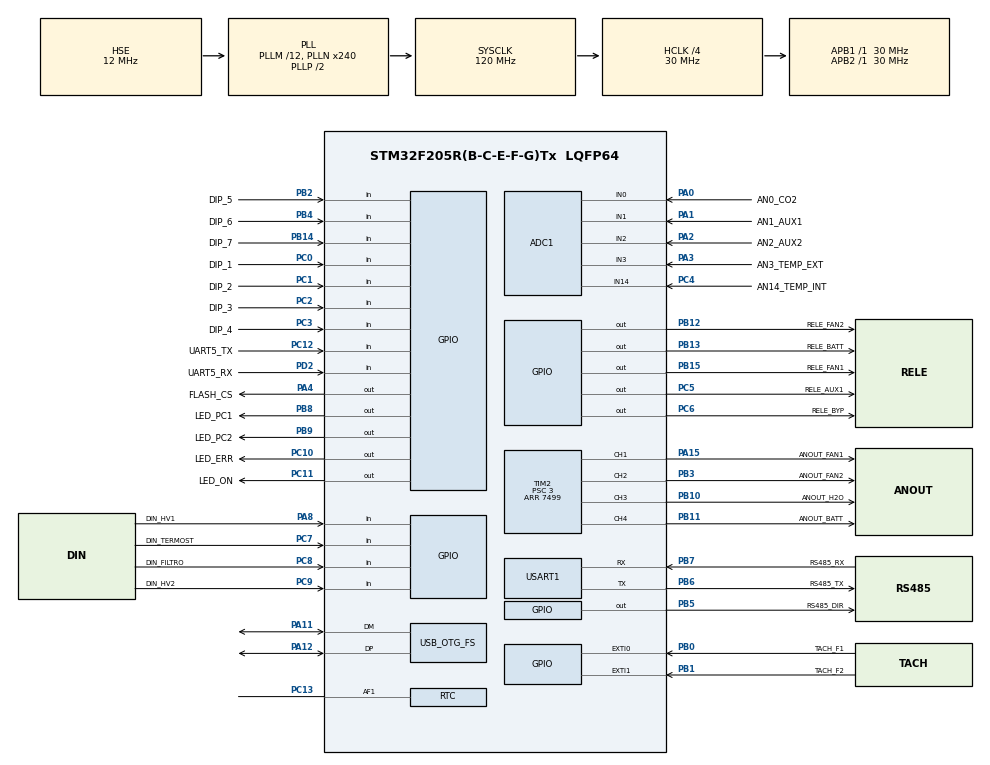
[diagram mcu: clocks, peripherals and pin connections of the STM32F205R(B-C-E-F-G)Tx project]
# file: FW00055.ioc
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ADC1.Channel-0\#ChannelRegularConversion=ADC_CHANNEL_0
ADC1.Channel-1\#ChannelRegularConversion=ADC_CHANNEL_1
ADC1.Channel-2\#ChannelRegularConversion=ADC_CHANNEL_2
ADC1.Channel-3\#ChannelRegularConversion=ADC_CHANNEL_3
ADC1.Channel-4\#ChannelRegularConversion=ADC_CHANNEL_14
ADC1.ClockPrescaler=ADC_CLOCK_SYNC_PCLK_DIV2
ADC1.ContinuousConvMode=DISABLE
ADC1.DMAContinuousRequests=ENABLE
ADC1.EOCSelection=ADC_EOC_SEQ_CONV
ADC1.NbrOfConversion=5
ADC1.NbrOfConversionFlag=1
ADC1.Rank-0\#ChannelRegularConversion=1
ADC1.Rank-1\#ChannelRegularConversion=2
ADC1.Rank-2\#ChannelRegularConversion=3
ADC1.Rank-3\#ChannelRegularConversion=4
ADC1.Rank-4\#ChannelRegularConversion=5
ADC1.SamplingTime-0\#ChannelRegularConversion=ADC_SAMPLETIME_480CYCLES
ADC1.SamplingTime-1\#ChannelRegularConversion=ADC_SAMPLETIME_480CYCLES
ADC1.SamplingTime-2\#ChannelRegularConversion=ADC_SAMPLETIME_480CYCLES
ADC1.SamplingTime-3\#ChannelRegularConversion=ADC_SAMPLETIME_480CYCLES
ADC1.SamplingTime-4\#ChannelRegularConversion=ADC_SAMPLETIME_480CYCLES
ADC1.ScanConvMode=ENABLE
ADC1.master=1
Dma.ADC1.0.Direction=DMA_PERIPH_TO_MEMORY
Dma.ADC1.0.FIFOMode=DMA_FIFOMODE_DISABLE
Dma.ADC1.0.Instance=DMA2_Stream0
Dma.ADC1.0.MemDataAlignment=DMA_MDATAALIGN_HALFWORD
Dma.ADC1.0.MemInc=DMA_MINC_ENABLE
Dma.ADC1.0.Mode=DMA_CIRCULAR
Dma.ADC1.0.PeriphDataAlignment=DMA_PDATAALIGN_HALFWORD
Dma.ADC1.0.PeriphInc=DMA_PINC_DISABLE
Dma.ADC1.0.Priority=DMA_PRIORITY_LOW
Dma.Request0=ADC1
IWDG.Prescaler=IWDG_PRESCALER_16
Mcu.Family=STM32F2
Mcu.Name=STM32F205R(B-C-E-F-G)Tx
Mcu.Package=LQFP64
NVIC.DMA2_Stream0_IRQn=true\:0\:0\:false\:false\:true\:false\:true
NVIC.EXTI0_IRQn=true\:0\:0\:false\:false\:true\:true\:true
NVIC.EXTI1_IRQn=true\:0\:0\:false\:false\:true\:true\:true
NVIC.OTG_FS_IRQn=true\:0\:0\:false\:false\:true\:false\:true
NVIC.PriorityGroup=NVIC_PRIORITYGROUP_4
NVIC.USART1_IRQn=true\:0\:0\:false\:false\:true\:true\:true
PA0-WKUP.GPIO_Label=AN0_CO2
PA0-WKUP.Signal=ADCx_IN0
PA1.GPIO_Label=AN1_AUX1
PA1.Signal=ADCx_IN1
PA10.Signal=USB_OTG_FS_ID
PA11.Mode=Device_Only
PA11.Signal=USB_OTG_FS_DM
PA12.Mode=Device_Only
PA12.Signal=USB_OTG_FS_DP
PA13.Signal=SYS_JTMS-SWDIO
PA14.Signal=SYS_JTCK-SWCLK
PA15.GPIO_Label=ANOUT_FAN1
PA15.Signal=S_TIM2_CH1_ETR
PA2.GPIO_Label=AN2_AUX2
PA2.Signal=ADCx_IN2
PA3.GPIO_Label=AN3_TEMP_EXT
PA3.Signal=ADCx_IN3
PA4.GPIO_Label=FLASH_CS
PA4.Signal=GPIO_Output
PA5.GPIO_Label=FLASH_SCK
PA5.Signal=SPI1_SCK
PA6.GPIO_Label=FLASH_MISO
PA6.Signal=SPI1_MISO
PA7.GPIO_Label=FLASH_MOSI
PA7.Signal=SPI1_MOSI
PA8.GPIO_Label=DIN_HV1
PA8.Signal=GPIO_Input
PA9.Signal=USB_OTG_FS_VBUS
PB0.GPIO_Label=TACH_F1
PB0.Signal=GPXTI0
PB1.GPIO_Label=TACH_F2
PB1.Signal=GPXTI1
PB10.GPIO_Label=ANOUT_H2O
PB10.Signal=S_TIM2_CH3
PB11.GPIO_Label=ANOUT_BATT
PB11.Signal=S_TIM2_CH4
PB12.GPIO_Label=RELE_FAN2
PB12.Signal=GPIO_Output
PB13.GPIO_Label=RELE_BATT
PB13.Signal=GPIO_Output
PB14.GPIO_Label=DIP_7
PB14.GPIO_PuPd=GPIO_PULLUP
PB14.Signal=GPIO_Input
PB15.GPIO_Label=RELE_FAN1
PB15.Signal=GPIO_Output
PB2.GPIO_Label=DIP_5
PB2.GPIO_PuPd=GPIO_PULLUP
PB2.Signal=GPIO_Input
PB3.GPIO_Label=ANOUT_FAN2
PB3.Signal=S_TIM2_CH2
PB4.GPIO_Label=DIP_6
PB4.GPIO_PuPd=GPIO_PULLUP
PB4.Signal=GPIO_Input
PB5.GPIO_Label=RS485_DIR
PB5.Signal=GPIO_Output
PB6.GPIO_Label=RS485_TX
PB6.GPIO_PuPd=GPIO_PULLUP
PB6.Mode=Asynchronous
PB6.Signal=USART1_TX
PB7.GPIO_Label=RS485_RX
PB7.Mode=Asynchronous
PB7.Signal=USART1_RX
PB8.GPIO_Label=LED_PC1
PB8.PinState=GPIO_PIN_SET
PB8.Signal=GPIO_Output
PB9.GPIO_Label=LED_PC2
PB9.PinState=GPIO_PIN_SET
PB9.Signal=GPIO_Output
PC0.GPIO_Label=DIP_1
PC0.GPIO_PuPd=GPIO_PULLUP
PC0.Signal=GPIO_Input
PC1.GPIO_Label=DIP_2
PC1.GPIO_PuPd=GPIO_PULLUP
PC1.Signal=GPIO_Input
PC10.GPIO_Label=LED_ERR
PC10.PinState=GPIO_PIN_SET
PC10.Signal=GPIO_Output
PC11.GPIO_Label=LED_ON
PC11.PinState=GPIO_PIN_SET
PC11.Signal=GPIO_Output
PC12.GPIO_Label=UART5_TX
PC12.GPIO_PuPd=GPIO_PULLUP
PC12.Signal=GPIO_Input
PC13.Mode=Calibration_512Hz
PC13.Signal=RTC_AF1
PC14-OSC32_IN.Mode=LSE-External-Oscillator
PC14-OSC32_IN.Signal=RCC_OSC32_IN
PC15-OSC32_OUT.Mode=LSE-External-Oscillator
PC15-OSC32_OUT.Signal=RCC_OSC32_OUT
PC2.GPIO_Label=DIP_3
PC2.GPIO_PuPd=GPIO_PULLUP
PC2.Signal=GPIO_Input
PC3.GPIO_Label=DIP_4
PC3.GPIO_PuPd=GPIO_PULLUP
PC3.Signal=GPIO_Input
PC4.GPIO_Label=AN14_TEMP_INT
PC4.Signal=ADCx_IN14
PC5.GPIO_Label=RELE_AUX1
PC5.Signal=GPIO_Output
PC6.GPIO_Label=RELE_BYP
PC6.Signal=GPIO_Output
PC7.GPIO_Label=DIN_TERMOST
PC7.Signal=GPIO_Input
PC8.GPIO_Label=DIN_FILTRO
PC8.Signal=GPIO_Input
PC9.GPIO_Label=DIN_HV2
PC9.Signal=GPIO_Input
PD2.GPIO_Label=UART5_RX
PD2.GPIO_PuPd=GPIO_PULLUP
PD2.Signal=GPIO_Input
PH0-OSC_IN.Mode=HSE-External-Oscillator
PH0-OSC_IN.Signal=RCC_OSC_IN
PH1-OSC_OUT.Mode=HSE-External-Oscillator
PH1-OSC_OUT.Signal=RCC_OSC_OUT
ProjectManager.HeapSize=0x800
ProjectManager.StackSize=0x1000
ProjectManager.TargetToolchain=TrueSTUDIO
RCC.48MHZClocksFreq_Value=48000000
RCC.AHBCLKDivider=RCC_SYSCLK_DIV4
RCC.AHBFreq_Value=30000000
RCC.APB1Freq_Value=30000000
RCC.APB1TimFreq_Value=30000000
RCC.APB2Freq_Value=30000000
RCC.APB2TimFreq_Value=30000000
RCC.CortexFreq_Value=30000000
RCC.HCLKFreq_Value=30000000
RCC.HSE_VALUE=12000000
RCC.HSI_VALUE=16000000
RCC.PLLM=12
RCC.PLLN=240
RCC.PLLQ=5
RCC.PLLSourceVirtual=RCC_PLLSOURCE_HSE
RCC.RCC_RTC_Clock_Source=RCC_RTCCLKSOURCE_LSE
RCC.RCC_RTC_Clock_SourceVirtual=RCC_RTCCLKSOURCE_LSE
RCC.SYSCLKFreq_VALUE=120000000
RCC.SYSCLKSource=RCC_SYSCLKSOURCE_PLLCLK
RCC.VCOOutputFreq_Value=240000000
SH.ADCx_IN0.0=ADC1_IN0,IN0
SH.ADCx_IN1.0=ADC1_IN1,IN1
SH.ADCx_IN14.0=ADC1_IN14,IN14
SH.ADCx_IN2.0=ADC1_IN2,IN2
SH.ADCx_IN3.0=ADC1_IN3,IN3
SH.S_TIM2_CH1_ETR.0=TIM2_CH1,PWM Generation1 CH1
SH.S_TIM2_CH2.0=TIM2_CH2,PWM Generation2 CH2
SH.S_TIM2_CH3.0=TIM2_CH3,PWM Generation3 CH3
SH.S_TIM2_CH4.0=TIM2_CH4,PWM Generation4 CH4
TIM2.Channel-PWM\ Generation1\ CH1=TIM_CHANNEL_1
TIM2.Channel-PWM\ Generation2\ CH2=TIM_CHANNEL_2
TIM2.Channel-PWM\ Generation3\ CH3=TIM_CHANNEL_3
TIM2.Channel-PWM\ Generation4\ CH4=TIM_CHANNEL_4
TIM2.Period=7499
TIM2.Prescaler=3
USART1.VirtualMode=VM_ASYNC
USB_DEVICE.CLASS_NAME_FS=CDC
USB_DEVICE.VirtualMode-CDC_FS=Cdc
USB_DEVICE.VirtualModeFS=Cdc_FS
USB_OTG_FS.VirtualMode=Device_Only
VP_CRC_VS_CRC.Mode=CRC_Activate
VP_IWDG_VS_IWDG.Mode=IWDG_Activate
VP_RTC_VS_RTC_Activate.Mode=RTC_Enabled
VP_TIM2_VS_ClockSourceINT.Mode=Internal
VP_USB_DEVICE_VS_USB_DEVICE_CDC_FS.Mode=CDC_FS
board=custom

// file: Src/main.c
/* USER CODE BEGIN Header */
/**
  ******************************************************************************
  * @file           : main.c
  * @brief          : Main program body
  ******************************************************************************
  ** This notice applies to any and all portions of this file
  * that are not between comment pairs USER CODE BEGIN and
  * USER CODE END. Other portions of this file, whether
  * inserted by the user or by software development tools
  * are owned by their respective copyright owners.
  *
  * COPYRIGHT(c) 2019 STMicroelectronics
  *
  * Redistribution and use in source and binary forms, with or without modification,
  * are permitted provided that the following conditions are met:
  *   1. Redistributions of source code must retain the above copyright notice,
  *      this list of conditions and the following disclaimer.
  *   2. Redistributions in binary form must reproduce the above copyright notice,
  *      this list of conditions and the following disclaimer in the documentation
  *      and/or other materials provided with the distribution.
  *   3. Neither the name of STMicroelectronics nor the names of its contributors
  *      may be used to endorse or promote products derived from this software
  *      without specific prior written permission.
  *
  * THIS SOFTWARE IS PROVIDED BY THE COPYRIGHT HOLDERS AND CONTRIBUTORS "AS IS"
  * AND ANY EXPRESS OR IMPLIED WARRANTIES, INCLUDING, BUT NOT LIMITED TO, THE
  * IMPLIED WARRANTIES OF MERCHANTABILITY AND FITNESS FOR A PARTICULAR PURPOSE ARE
  * DISCLAIMED. IN NO EVENT SHALL THE COPYRIGHT HOLDER OR CONTRIBUTORS BE LIABLE
  * FOR ANY DIRECT, INDIRECT, INCIDENTAL, SPECIAL, EXEMPLARY, OR CONSEQUENTIAL
  * DAMAGES (INCLUDING, BUT NOT LIMITED TO, PROCUREMENT OF SUBSTITUTE GOODS OR
  * SERVICES; LOSS OF USE, DATA, OR PROFITS; OR BUSINESS INTERRUPTION) HOWEVER
  * CAUSED AND ON ANY THEORY OF LIABILITY, WHETHER IN CONTRACT, STRICT LIABILITY,
  * OR TORT (INCLUDING NEGLIGENCE OR OTHERWISE) ARISING IN ANY WAY OUT OF THE USE
  * OF THIS SOFTWARE, EVEN IF ADVISED OF THE POSSIBILITY OF SUCH DAMAGE.
  *
  ******************************************************************************
  */
/* USER CODE END Header */

#include "main.h"
#include "adc.h"
#include "crc.h"
#include "dma.h"
#include "iwdg.h"
#include "rtc.h"
#include "tim.h"
#include "usart.h"
#include "usb_device.h"
#include "gpio.h"

/* USER CODE BEGIN Includes */
#include "application.h"
/* USER CODE END Includes */

void SystemClock_Config(void);

int main(void)
{

  /* MCU Configuration--------------------------------------------------------*/

  /* Reset of all peripherals, Initializes the Flash interface and the Systick. */
  HAL_Init();

  /* Configure the system clock */
  SystemClock_Config();

  /* Initialize all configured peripherals */
  MX_GPIO_Init();
  MX_DMA_Init();
  MX_RTC_Init();
  MX_TIM2_Init();
  MX_USART1_UART_Init();
  MX_CRC_Init();
  MX_IWDG_Init();
  MX_USB_DEVICE_Init();
  MX_ADC1_Init();

  /* Infinite loop */
  /* USER CODE BEGIN WHILE */
  while (1)
  {
	  Application_Run();

    /* USER CODE END WHILE */

  }
}

void SystemClock_Config(void)
{
  RCC_OscInitTypeDef RCC_OscInitStruct = {0};
  RCC_ClkInitTypeDef RCC_ClkInitStruct = {0};
  RCC_PeriphCLKInitTypeDef PeriphClkInitStruct = {0};

  /** Initializes the CPU, AHB and APB busses clocks
  */
  RCC_OscInitStruct.OscillatorType = RCC_OSCILLATORTYPE_LSI|RCC_OSCILLATORTYPE_HSE
                              |RCC_OSCILLATORTYPE_LSE;
  RCC_OscInitStruct.HSEState = RCC_HSE_ON;
  RCC_OscInitStruct.LSEState = RCC_LSE_ON;
  RCC_OscInitStruct.LSIState = RCC_LSI_ON;
  RCC_OscInitStruct.PLL.PLLState = RCC_PLL_ON;
  RCC_OscInitStruct.PLL.PLLSource = RCC_PLLSOURCE_HSE;
  RCC_OscInitStruct.PLL.PLLM = 12;
  RCC_OscInitStruct.PLL.PLLN = 240;
  RCC_OscInitStruct.PLL.PLLP = RCC_PLLP_DIV2;
  RCC_OscInitStruct.PLL.PLLQ = 5;
  if (HAL_RCC_OscConfig(&RCC_OscInitStruct) != HAL_OK)
  {
    Error_Handler();
  }
  /** Initializes the CPU, AHB and APB busses clocks
  */
  RCC_ClkInitStruct.ClockType = RCC_CLOCKTYPE_HCLK|RCC_CLOCKTYPE_SYSCLK
                              |RCC_CLOCKTYPE_PCLK1|RCC_CLOCKTYPE_PCLK2;
  RCC_ClkInitStruct.SYSCLKSource = RCC_SYSCLKSOURCE_PLLCLK;
  RCC_ClkInitStruct.AHBCLKDivider = RCC_SYSCLK_DIV4;
  RCC_ClkInitStruct.APB1CLKDivider = RCC_HCLK_DIV1;
  RCC_ClkInitStruct.APB2CLKDivider = RCC_HCLK_DIV1;

  if (HAL_RCC_ClockConfig(&RCC_ClkInitStruct, FLASH_LATENCY_0) != HAL_OK)
  {
    Error_Handler();
  }
  PeriphClkInitStruct.PeriphClockSelection = RCC_PERIPHCLK_RTC;
  PeriphClkInitStruct.RTCClockSelection = RCC_RTCCLKSOURCE_LSE;
  if (HAL_RCCEx_PeriphCLKConfig(&PeriphClkInitStruct) != HAL_OK)
  {
    Error_Handler();
  }
}

void Error_Handler(void)
{
}

/************************ (C) COPYRIGHT STMicroelectronics *****END OF FILE****/
